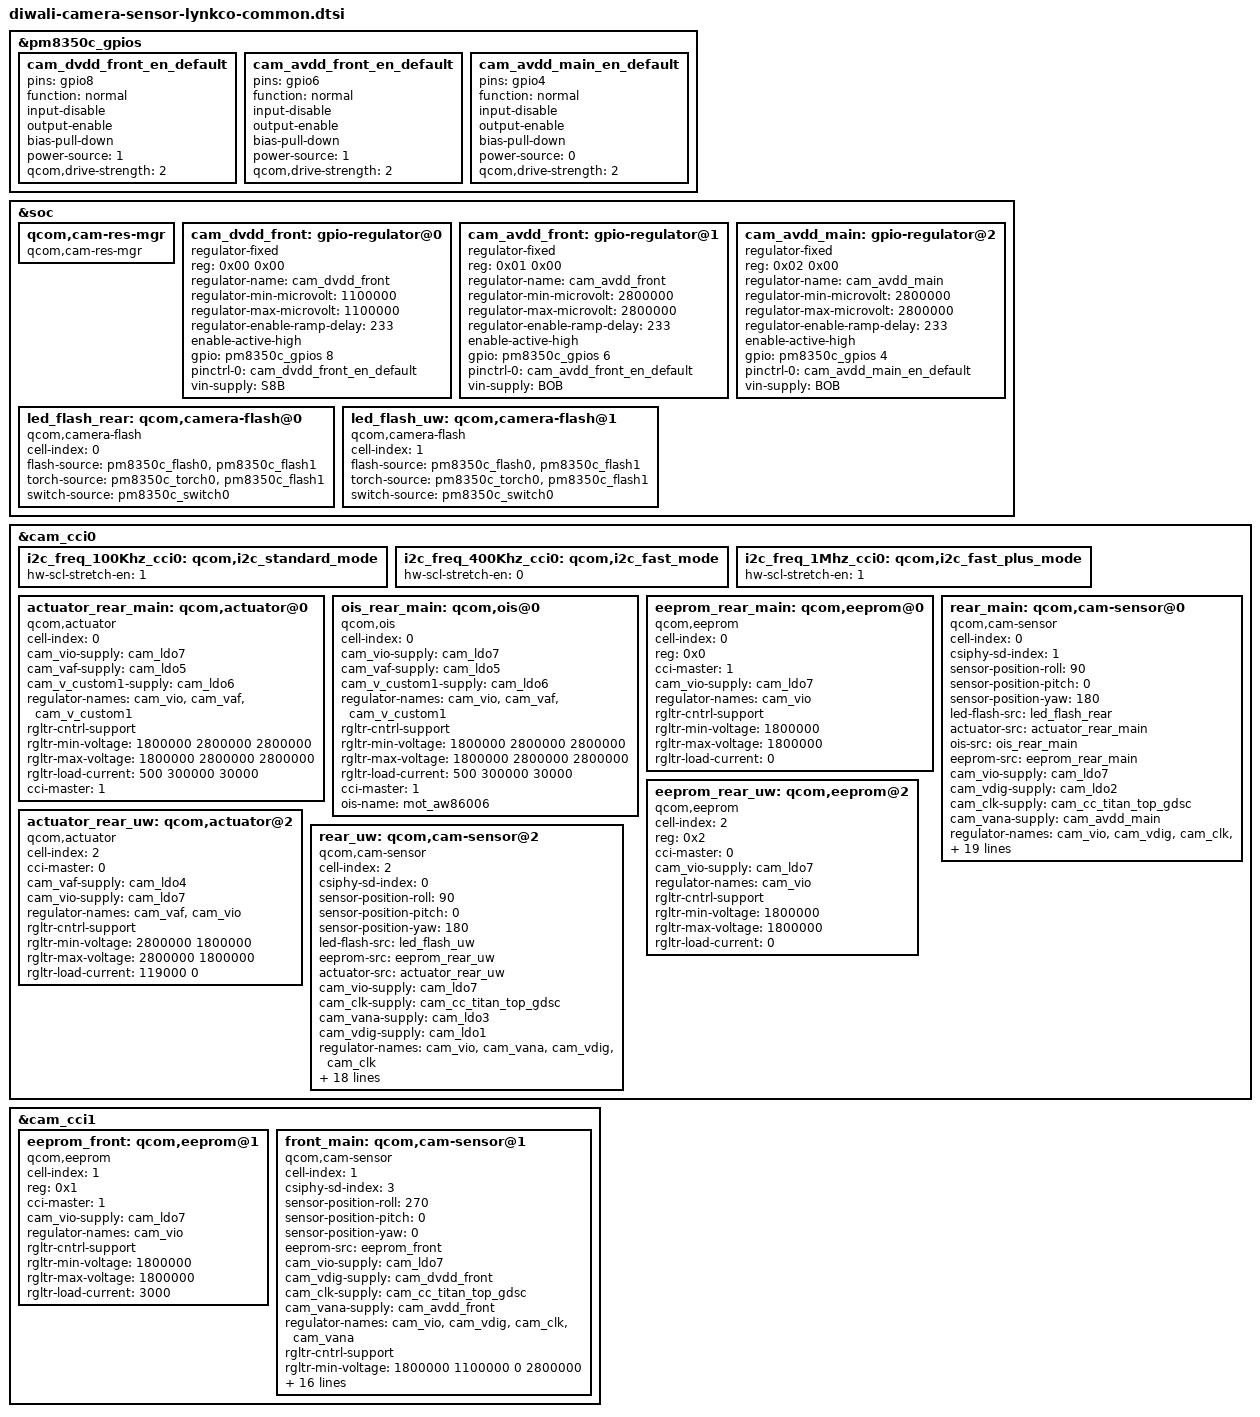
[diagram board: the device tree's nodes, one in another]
/*
   This base is original from "diwali-camera-sensor-idp.dtsi"
*/
#include <dt-bindings/clock/qcom,camcc-diwali.h>
#include <dt-bindings/msm-camera.h>

&pm8350c_gpios {
		/delete-node/ lcd_backlight_ctrl_default;

		cam_dvdd_front_en_default: cam_dvdd_front_en_default {
			pins = "gpio8";
			function = "normal";
			input-disable;
			output-enable;
			bias-pull-down; /* PULL DOWN */
			power-source = <1>;	/* 1.8V */
			qcom,drive-strength = <2>;	/* Medium */
		};

		cam_avdd_front_en_default: cam_avdd_front_en_default {
			pins = "gpio6";
			function = "normal";
			input-disable;
			output-enable;
			bias-pull-down; /* PULL DOWN */
			power-source = <1>;	/* 1.8V */
			qcom,drive-strength = <2>;	/* Medium */
		};

		cam_avdd_main_en_default: cam_avdd_main_en_default {
			pins = "gpio4";
			function = "normal";
			input-disable;
			output-enable;
			bias-pull-down; /* PULL DOWN */
			power-source = <0>;	/* 1.8V */
			qcom,drive-strength = <2>;	/* Medium */
		};
};

&soc {
	qcom,cam-res-mgr {
		compatible = "qcom,cam-res-mgr";
		status = "ok";
	};

	cam_dvdd_front: gpio-regulator@0 {
		compatible = "regulator-fixed";
		reg = <0x00 0x00>;
		regulator-name = "cam_dvdd_front";
		regulator-min-microvolt = <1100000>;
		regulator-max-microvolt = <1100000>;
		regulator-enable-ramp-delay = <233>;
		enable-active-high;
		gpio = <&pm8350c_gpios 8 0>;
		pinctrl-names = "default";
		pinctrl-0 = <&cam_dvdd_front_en_default>;
		vin-supply = <&S8B>;
	};

	cam_avdd_front: gpio-regulator@1 {
		compatible = "regulator-fixed";
		reg = <0x01 0x00>;
		regulator-name = "cam_avdd_front";
		regulator-min-microvolt = <2800000>;
		regulator-max-microvolt = <2800000>;
		regulator-enable-ramp-delay = <233>;
		enable-active-high;
		gpio = <&pm8350c_gpios 6 0>;
		pinctrl-names = "default";
		pinctrl-0 = <&cam_avdd_front_en_default>;
		vin-supply = <&BOB>;
	};

	cam_avdd_main: gpio-regulator@2 {
		compatible = "regulator-fixed";
		reg = <0x02 0x00>;
		regulator-name = "cam_avdd_main";
		regulator-min-microvolt = <2800000>;
		regulator-max-microvolt = <2800000>;
		regulator-enable-ramp-delay = <233>;
		enable-active-high;
		gpio = <&pm8350c_gpios 4 0>;
		pinctrl-names = "default";
		pinctrl-0 = <&cam_avdd_main_en_default>;
		vin-supply = <&BOB>;
	};

	led_flash_rear: qcom,camera-flash@0 {
		cell-index = <0>;
		compatible = "qcom,camera-flash";
		flash-source = <&pm8350c_flash0 &pm8350c_flash1>;
		torch-source = <&pm8350c_torch0 &pm8350c_flash1>;
		switch-source = <&pm8350c_switch0>;
		status = "ok";
	};

	led_flash_uw: qcom,camera-flash@1 {
		cell-index = <1>;
		compatible = "qcom,camera-flash";
		flash-source = <&pm8350c_flash0 &pm8350c_flash1>;
		torch-source = <&pm8350c_torch0 &pm8350c_flash1>;
		switch-source = <&pm8350c_switch0>;
		status = "ok";
	};
};

&cam_cci0 {
	i2c_freq_100Khz_cci0: qcom,i2c_standard_mode {
		hw-scl-stretch-en = <1>;
	};

	i2c_freq_400Khz_cci0: qcom,i2c_fast_mode {
		hw-scl-stretch-en = <0>;
	};

	i2c_freq_1Mhz_cci0: qcom,i2c_fast_plus_mode {
		hw-scl-stretch-en = <1>;
	};

	actuator_rear_main: qcom,actuator@0 {
		cell-index = <0>;
		compatible = "qcom,actuator";
		cam_vio-supply = <&cam_ldo7>;
		cam_vaf-supply = <&cam_ldo5>;
		cam_v_custom1-supply = <&cam_ldo6>;
		regulator-names = "cam_vio", "cam_vaf", "cam_v_custom1";
		rgltr-cntrl-support;
		rgltr-min-voltage = <1800000 2800000 2800000>;
		rgltr-max-voltage = <1800000 2800000 2800000>;
		rgltr-load-current = <500 300000 30000>;
		cci-master = <1>;
		status = "ok";
	};

	ois_rear_main: qcom,ois@0 {
		cell-index = <0>;
		compatible = "qcom,ois";
		cam_vio-supply = <&cam_ldo7>;
		cam_vaf-supply = <&cam_ldo5>;
		cam_v_custom1-supply = <&cam_ldo6>;
		regulator-names = "cam_vio", "cam_vaf", "cam_v_custom1";
		rgltr-cntrl-support;
		rgltr-min-voltage = <1800000 2800000 2800000>;
		rgltr-max-voltage = <1800000 2800000 2800000>;
		rgltr-load-current = <500 300000 30000>;
		cci-master = <1>;
		status = "ok";
		ois-name = "mot_aw86006";
	};

	eeprom_rear_main: qcom,eeprom@0 {
		cell-index = <0>;
		reg = <0x0>;
		compatible = "qcom,eeprom";
		cci-master = <1>;
		cam_vio-supply = <&cam_ldo7>;
		regulator-names = "cam_vio";
		rgltr-cntrl-support;
		rgltr-min-voltage = <1800000>;
		rgltr-max-voltage = <1800000>;
		rgltr-load-current = <0>;
		status = "ok";
	};

	rear_main: qcom,cam-sensor@0 {
		cell-index = <0>;
		compatible = "qcom,cam-sensor";
		csiphy-sd-index = <1>;
		sensor-position-roll = <90>;
		sensor-position-pitch = <0>;
		sensor-position-yaw = <180>;
		led-flash-src = <&led_flash_rear>;
		actuator-src = <&actuator_rear_main>;
		ois-src = <&ois_rear_main>;
		eeprom-src = <&eeprom_rear_main>;
		cam_vio-supply = <&cam_ldo7>;
		cam_vdig-supply = <&cam_ldo2>;
		cam_clk-supply = <&cam_cc_titan_top_gdsc>;
		cam_vana-supply = <&cam_avdd_main>;
		regulator-names = "cam_vio", "cam_vdig",
			"cam_clk", "cam_vana";
		rgltr-cntrl-support;
		rgltr-min-voltage = <1800000 1100000 0 2800000>;
		rgltr-max-voltage = <1800000 1100000 0 2800000>;
		rgltr-load-current = <155000 680000 0 50000>;
		gpio-no-mux = <0>;
		pinctrl-names = "cam_default", "cam_suspend";
		pinctrl-0 = <&cam_sensor_mclk1_active
			&cam_sensor_active_rst1>;
		pinctrl-1 = <&cam_sensor_mclk1_suspend
			&cam_sensor_suspend_rst1>;
		gpios = <&tlmm 65 0>,
			<&tlmm 21 0>;
		gpio-reset = <1>;
		gpio-req-tbl-num = <0 1>;
		gpio-req-tbl-flags = <1 0>;
		gpio-req-tbl-label = "CAMIF_MCLK1",
					"CAM_RESET1";
		cci-master = <1>;
		clocks = <&camcc CAM_CC_MCLK1_CLK>;
		clock-names = "cam_clk";
		clock-cntl-level = "nominal";
		clock-rates = <24000000>;
		status = "ok";
	};

	eeprom_rear_uw: qcom,eeprom@2 {
		cell-index = <2>;
		reg = <0x2>;
		compatible = "qcom,eeprom";
		cci-master = <0>;
		cam_vio-supply = <&cam_ldo7>;
		regulator-names = "cam_vio";
		rgltr-cntrl-support;
		rgltr-min-voltage = <1800000>;
		rgltr-max-voltage = <1800000>;
		rgltr-load-current = <0>;
	};

	actuator_rear_uw: qcom,actuator@2 {
		cell-index = <2>;
		compatible = "qcom,actuator";
		cci-master = <0>;
		cam_vaf-supply = <&cam_ldo4>;
		cam_vio-supply = <&cam_ldo7>;
		regulator-names = "cam_vaf", "cam_vio";
		rgltr-cntrl-support;
		rgltr-min-voltage = <2800000 1800000>;
		rgltr-max-voltage = <2800000 1800000>;
		rgltr-load-current = <119000 0>;
		status = "ok";
	};

	rear_uw: qcom,cam-sensor@2 {
		cell-index = <2>;
		compatible = "qcom,cam-sensor";
		csiphy-sd-index = <0>;
		sensor-position-roll = <90>;
		sensor-position-pitch = <0>;
		sensor-position-yaw = <180>;
		led-flash-src = <&led_flash_uw>;
		eeprom-src = <&eeprom_rear_uw>;
		actuator-src = <&actuator_rear_uw>;
		cam_vio-supply = <&cam_ldo7>;
		cam_clk-supply = <&cam_cc_titan_top_gdsc>;
		cam_vana-supply = <&cam_ldo3>;
		cam_vdig-supply = <&cam_ldo1>;
		regulator-names = "cam_vio", "cam_vana",
			"cam_vdig", "cam_clk";
		rgltr-cntrl-support;
		rgltr-min-voltage = <1800000 2800000 1100000 0>;
		rgltr-max-voltage = <1800000 2800000 1100000 0>;
		rgltr-load-current = <7000 132000 405000 0>;
		gpio-no-mux = <0>;
		pinctrl-names = "cam_default", "cam_suspend";
		pinctrl-0 = <&cam_sensor_mclk0_active
			&cam_sensor_active_rst0>;
		pinctrl-1 = <&cam_sensor_mclk0_suspend
			&cam_sensor_suspend_rst0>;
		gpios = <&tlmm 64 0>,
			<&tlmm 20 0>;
		gpio-reset = <1>;
		gpio-req-tbl-num = <0 1>;
		gpio-req-tbl-flags = <1 0>;
		gpio-req-tbl-label = "CAMIF_MCLK0",
			"CAM_RESET0";
		cci-master = <0>;
		clocks = <&camcc CAM_CC_MCLK0_CLK>;
		clock-names = "cam_clk";
		clock-cntl-level = "nominal";
		clock-rates = <24000000>;
		status = "ok";
    };
};

&cam_cci1 {
	eeprom_front: qcom,eeprom@1 {
		cell-index = <1>;
		reg = <0x1>;
		compatible = "qcom,eeprom";
		cci-master = <1>;
		cam_vio-supply = <&cam_ldo7>;
		regulator-names = "cam_vio";
		rgltr-cntrl-support;
		rgltr-min-voltage = <1800000>;
		rgltr-max-voltage = <1800000>;
		rgltr-load-current = <3000>;
	};

	front_main: qcom,cam-sensor@1 {
		cell-index = <1>;
		compatible = "qcom,cam-sensor";
		csiphy-sd-index = <3>;
		sensor-position-roll = <270>;
		sensor-position-pitch = <0>;
		sensor-position-yaw = <0>;
		eeprom-src = <&eeprom_front>;
		cam_vio-supply = <&cam_ldo7>;
		cam_vdig-supply = <&cam_dvdd_front>;
		cam_clk-supply = <&cam_cc_titan_top_gdsc>;
		cam_vana-supply = <&cam_avdd_front>;
		regulator-names = "cam_vio", "cam_vdig",
			"cam_clk", "cam_vana";
		rgltr-cntrl-support;
		rgltr-min-voltage = <1800000 1100000 0 2800000>;
		rgltr-max-voltage = <1800000 1100000 0 2800000>;
		rgltr-load-current = <3000 283000 0 50000>;
		gpio-no-mux = <0>;
		pinctrl-names = "cam_default", "cam_suspend";
		pinctrl-0 = <&cam_sensor_mclk3_active
			&cam_sensor_active_rst3>;
		pinctrl-1 = <&cam_sensor_mclk3_suspend
			&cam_sensor_suspend_rst3>;
		gpios = <&tlmm 67 0>,
			<&tlmm 79 0>;
		gpio-reset = <1>;
		gpio-req-tbl-num = <0 1>;
		gpio-req-tbl-flags = <1 0>;
		gpio-req-tbl-label = "CAMIF_MCLK3",
					"CAM_RESET3";
		cci-master = <1>;
		clocks = <&camcc CAM_CC_MCLK3_CLK>;
		clock-names = "cam_clk";
		clock-cntl-level = "nominal";
		clock-rates = <24000000>;
		status = "ok";
	};
};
